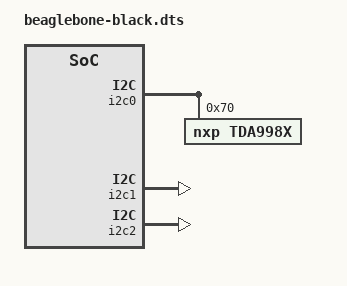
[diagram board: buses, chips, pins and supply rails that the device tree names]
/*-
 * Copyright (c) 2015 Oleksandr Tymoshenko <gonzo@freebsd.org>
 * All rights reserved.
 *
 * Redistribution and use in source and binary forms, with or without
 * modification, are permitted provided that the following conditions
 * are met:
 * 1. Redistributions of source code must retain the above copyright
 *    notice, this list of conditions and the following disclaimer.
 * 2. Redistributions in binary form must reproduce the above copyright
 *    notice, this list of conditions and the following disclaimer in the
 *    documentation and/or other materials provided with the distribution.
 *
 * THIS SOFTWARE IS PROVIDED BY THE AUTHOR AND CONTRIBUTORS ``AS IS'' AND
 * ANY EXPRESS OR IMPLIED WARRANTIES, INCLUDING, BUT NOT LIMITED TO, THE
 * IMPLIED WARRANTIES OF MERCHANTABILITY AND FITNESS FOR A PARTICULAR PURPOSE
 * ARE DISCLAIMED.  IN NO EVENT SHALL THE AUTHOR OR CONTRIBUTORS BE LIABLE
 * FOR ANY DIRECT, INDIRECT, INCIDENTAL, SPECIAL, EXEMPLARY, OR CONSEQUENTIAL
 * DAMAGES (INCLUDING, BUT NOT LIMITED TO, PROCUREMENT OF SUBSTITUTE GOODS
 * OR SERVICES; LOSS OF USE, DATA, OR PROFITS; OR BUSINESS INTERRUPTION)
 * HOWEVER CAUSED AND ON ANY THEORY OF LIABILITY, WHETHER IN CONTRACT, STRICT
 * LIABILITY, OR TORT (INCLUDING NEGLIGENCE OR OTHERWISE) ARISING IN ANY WAY
 * OUT OF THE USE OF THIS SOFTWARE, EVEN IF ADVISED OF THE POSSIBILITY OF
 * SUCH DAMAGE.
 * 
 * $FreeBSD$
 */


#include "am335x-boneblack.dts"
#include "beaglebone-common.dtsi"

&am33xx_pinmux {
	i2c1_pins: pinmux_i2c1_pins {
		pinctrl-single,pins = <
			0x158 (PIN_INPUT_PULLUP | MUX_MODE2)	/* spi0_d1.i2c1_sda */
			0x15c (PIN_INPUT_PULLUP | MUX_MODE2)	/* spi0_cs0.i2c1_scl */
		>;
	};

	i2c2_pins: pinmux_i2c2_pins {
		pinctrl-single,pins = <
			0x178 (PIN_INPUT_PULLUP | MUX_MODE3)	/* uart1_ctsn.i2c2_sda */
			0x17c (PIN_INPUT_PULLUP | MUX_MODE3)	/* uart1_rtsn.i2c2_scl */
		>;
	};
};

&i2c0 {
	tda998x: hdmi-encoder {
		compatible = "nxp,tda998x";
		reg = <0x70>;

 		pinctrl-names = "default", "off";
 		pinctrl-0 = <&nxp_hdmi_bonelt_pins>;
 		pinctrl-1 = <&nxp_hdmi_bonelt_off_pins>;
		status = "okay";
 	};
};

&i2c1 {
	pinctrl-names = "default";
	pinctrl-0 = <&i2c1_pins>;

	status = "okay";
};

&i2c2 {
	pinctrl-names = "default";
	pinctrl-0 = <&i2c2_pins>;

	status = "okay";
};

&lcdc {
	hdmi = <&tda998x>;
};

/ {
	hdmi {
		status = "disabled";
	};
};
